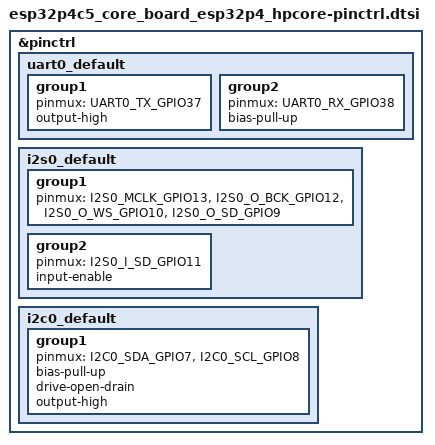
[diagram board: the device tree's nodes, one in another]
/*
 * Copyright (c) 2026 Tessera Project
 *
 * SPDX-License-Identifier: Apache-2.0
 */

#include <zephyr/dt-bindings/pinctrl/esp-pinctrl-common.h>
#include <zephyr/dt-bindings/pinctrl/esp32p4-pinctrl.h>
#include <zephyr/dt-bindings/pinctrl/esp32p4-gpio-sigmap.h>

&pinctrl {
	uart0_default: uart0_default {
		/* Carrier schematic V1.5, USB TO UART block: the CH343 bridge
		 * (U9) drives DBG_TXD -> GPIO38 (the P4's UART0 RXD) and reads
		 * GPIO37 (the P4's UART0 TXD) on DBG_RXD; the same block drives
		 * the P4 reset (CHIP_PU) and BOOT (GPIO35) for auto-download,
		 * GPIO36 is pulled up 10K. */
		group1 {
			pinmux = <UART0_TX_GPIO37>;
			output-high;
		};

		group2 {
			pinmux = <UART0_RX_GPIO38>;
			bias-pull-up;
		};
	};

	i2s0_default: i2s0_default {
		group1 {
			/* Carrier schematic V1.5, Audio CODEC block (U11 ES8311):
			 * MCLK=GPIO13, SCLK=GPIO12, LRCK=GPIO10, DSDIN (P4 out,
			 * codec input)=GPIO9, ASDOUT (codec out, P4 in)=GPIO11;
			 * the codec's I2C is SDA=GPIO7 / SCL=GPIO8 and the PA
			 * (NS4150B) enable is GPIO53 (net PACTRL). Confirmed
			 * against the vendor PDF 2026-11-24 — the earlier
			 * 2026-10-30 reading of carrier V1.3 said the same. */
			pinmux = <I2S0_MCLK_GPIO13>, <I2S0_O_BCK_GPIO12>,
				 <I2S0_O_WS_GPIO10>, <I2S0_O_SD_GPIO9>;
		};
		group2 {
			pinmux = <I2S0_I_SD_GPIO11>;
			input-enable;
		};
	};

	i2c0_default: i2c0_default {
		group1 {
			/* Carrier schematic V1.5: ES8311 CCLK=GPIO8 (I2C_SCL_GPIO8),
			 * CDATA=GPIO7 (I2C_SDA_GPIO7); the codec's CE is tied to
			 * ground, so the part is always enabled. */
			pinmux = <I2C0_SDA_GPIO7>,
				 <I2C0_SCL_GPIO8>;
			bias-pull-up;
			drive-open-drain;
			output-high;
		};
	};
};
